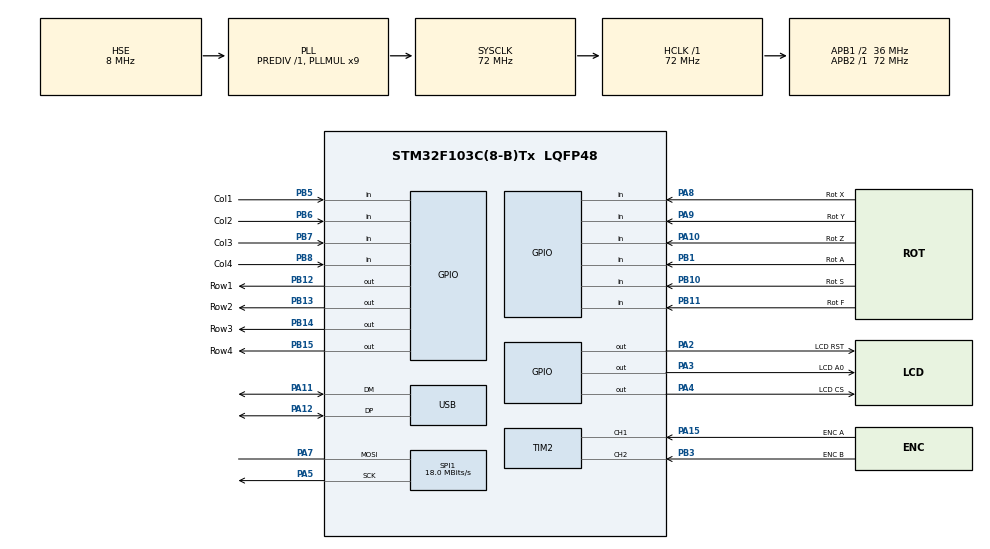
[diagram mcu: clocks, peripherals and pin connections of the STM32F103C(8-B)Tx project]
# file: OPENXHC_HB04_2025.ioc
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Dma.Request0=SPI1_TX
Dma.SPI1_TX.0.Direction=DMA_MEMORY_TO_PERIPH
Dma.SPI1_TX.0.Instance=DMA1_Channel3
Dma.SPI1_TX.0.MemDataAlignment=DMA_MDATAALIGN_BYTE
Dma.SPI1_TX.0.MemInc=DMA_MINC_ENABLE
Dma.SPI1_TX.0.Mode=DMA_NORMAL
Dma.SPI1_TX.0.PeriphDataAlignment=DMA_PDATAALIGN_BYTE
Dma.SPI1_TX.0.PeriphInc=DMA_PINC_DISABLE
Dma.SPI1_TX.0.Priority=DMA_PRIORITY_HIGH
Mcu.Family=STM32F1
Mcu.Name=STM32F103C(8-B)Tx
Mcu.Package=LQFP48
NVIC.DMA1_Channel3_IRQn=true\:0\:0\:false\:false\:true\:false\:true\:true
NVIC.PriorityGroup=NVIC_PRIORITYGROUP_4
NVIC.USB_LP_CAN1_RX0_IRQn=true\:0\:0\:false\:false\:true\:false\:true\:true
PA10.GPIO_Label=Rot Z
PA10.GPIO_PuPd=GPIO_PULLUP
PA10.Signal=GPIO_Input
PA11.Mode=Device
PA11.Signal=USB_DM
PA12.Mode=Device
PA12.Signal=USB_DP
PA13.Mode=Serial_Wire
PA13.Signal=SYS_JTMS-SWDIO
PA14.Mode=Serial_Wire
PA14.Signal=SYS_JTCK-SWCLK
PA15.GPIO_Label=ENC A
PA15.GPIO_PuPd=GPIO_PULLUP
PA15.Signal=S_TIM2_CH1_ETR
PA2.GPIO_Label=LCD RST
PA2.Signal=GPIO_Output
PA3.GPIO_Label=LCD A0
PA3.Signal=GPIO_Output
PA4.GPIO_Label=LCD CS
PA4.Signal=GPIO_Output
PA5.Mode=Simplex_Bidirectional_Master
PA5.Signal=SPI1_SCK
PA7.Mode=Simplex_Bidirectional_Master
PA7.Signal=SPI1_MOSI
PA8.GPIO_Label=Rot X
PA8.GPIO_PuPd=GPIO_PULLUP
PA8.Signal=GPIO_Input
PA9.GPIO_Label=Rot Y
PA9.GPIO_PuPd=GPIO_PULLUP
PA9.Signal=GPIO_Input
PB1.GPIO_Label=Rot A
PB1.GPIO_PuPd=GPIO_PULLUP
PB1.Signal=GPIO_Input
PB10.GPIO_Label=Rot S
PB10.GPIO_PuPd=GPIO_PULLUP
PB10.Signal=GPIO_Input
PB11.GPIO_Label=Rot F
PB11.GPIO_PuPd=GPIO_PULLUP
PB11.Signal=GPIO_Input
PB12.GPIO_Label=Row1
PB12.GPIO_ModeDefaultOutputPP=GPIO_MODE_OUTPUT_OD
PB12.GPIO_PuPd=GPIO_NOPULL
PB12.Signal=GPIO_Output
PB13.GPIO_Label=Row2
PB13.GPIO_ModeDefaultOutputPP=GPIO_MODE_OUTPUT_OD
PB13.GPIO_PuPd=GPIO_NOPULL
PB13.Signal=GPIO_Output
PB14.GPIO_Label=Row3
PB14.GPIO_ModeDefaultOutputPP=GPIO_MODE_OUTPUT_OD
PB14.GPIO_PuPd=GPIO_NOPULL
PB14.Signal=GPIO_Output
PB15.GPIO_Label=Row4
PB15.GPIO_ModeDefaultOutputPP=GPIO_MODE_OUTPUT_OD
PB15.GPIO_PuPd=GPIO_NOPULL
PB15.Signal=GPIO_Output
PB3.GPIO_Label=ENC B
PB3.GPIO_PuPd=GPIO_PULLUP
PB3.Signal=S_TIM2_CH2
PB5.GPIO_Label=Col1
PB5.GPIO_PuPd=GPIO_PULLUP
PB5.Signal=GPIO_Input
PB6.GPIO_Label=Col2
PB6.GPIO_PuPd=GPIO_PULLUP
PB6.Signal=GPIO_Input
PB7.GPIO_Label=Col3
PB7.GPIO_PuPd=GPIO_PULLUP
PB7.Signal=GPIO_Input
PB8.GPIO_Label=Col4
PB8.GPIO_PuPd=GPIO_PULLUP
PB8.Signal=GPIO_Input
PD0-OSC_IN.Mode=HSE-External-Oscillator
PD0-OSC_IN.Signal=RCC_OSC_IN
PD1-OSC_OUT.Mode=HSE-External-Oscillator
PD1-OSC_OUT.Signal=RCC_OSC_OUT
ProjectManager.HeapSize=0x200
ProjectManager.StackSize=0x400
ProjectManager.TargetToolchain=STM32CubeIDE
RCC.AHBFreq_Value=72000000
RCC.APB1CLKDivider=RCC_HCLK_DIV2
RCC.APB1Freq_Value=36000000
RCC.APB1TimFreq_Value=72000000
RCC.APB2Freq_Value=72000000
RCC.APB2TimFreq_Value=72000000
RCC.HCLKFreq_Value=72000000
RCC.PLLMUL=RCC_PLL_MUL9
RCC.SYSCLKFreq_VALUE=72000000
RCC.SYSCLKSource=RCC_SYSCLKSOURCE_PLLCLK
RCC.USBFreq_Value=48000000
RCC.USBPrescaler=RCC_USBCLKSOURCE_PLL_DIV1_5
SH.S_TIM2_CH1_ETR.0=TIM2_CH1,Encoder_Interface
SH.S_TIM2_CH2.0=TIM2_CH2,Encoder_Interface
SPI1.BaudRatePrescaler=SPI_BAUDRATEPRESCALER_4
SPI1.CalculateBaudRate=18.0 MBits/s
SPI1.Direction=SPI_DIRECTION_1LINE
SPI1.Mode=SPI_MODE_MASTER
SPI1.VirtualType=VM_MASTER
TIM2.IC1Filter=4
TIM2.IC2Filter=4
USB_DEVICE.CLASS_NAME_FS=CUSTOM_HID
USB_DEVICE.USBD_CUSTOM_HID_REPORT_DESC_SIZE=41
USB_DEVICE.VirtualMode=CustomHid
USB_DEVICE.VirtualModeFS=Custom_Hid_FS
VP_USB_DEVICE_VS_USB_DEVICE_CUSTOM_HID_FS.Mode=CUSTOM_HID_FS
board=custom

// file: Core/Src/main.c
/* USER CODE BEGIN Header */
/**
  ******************************************************************************
  * @file           : main.c
  * @brief          : Main program body
  ******************************************************************************
  * @attention
  *
  * Copyright (c) 2025 STMicroelectronics.
  * All rights reserved.
  *
  * This software is licensed under terms that can be found in the LICENSE file
  * in the root directory of this software component.
  * If no LICENSE file comes with this software, it is provided AS-IS.
  *
  ******************************************************************************
  */
/* USER CODE END Header */
#include "main.h"
#include "dma.h"
#include "spi.h"
#include "tim.h"
#include "usb_device.h"
#include "gpio.h"

/* USER CODE BEGIN Includes */
#include "st7735.h"
#include "fonts.h"
#include "ui.h"
#include "xhc_integration.h"
/* USER CODE END Includes */

void SystemClock_Config(void);

int main(void)
{

  /* MCU Configuration--------------------------------------------------------*/

  /* Reset of all peripherals, Initializes the Flash interface and the Systick. */
  HAL_Init();

  /* Configure the system clock */
  SystemClock_Config();

  /* Initialize all configured peripherals */
  MX_GPIO_Init();
  MX_DMA_Init();
  MX_SPI1_Init();
  MX_USB_DEVICE_Init();
  MX_TIM2_Init();
  /* USER CODE BEGIN 2 */
  ST7735_Init();
  xhc_init();
  UI_DrawStatic();

  // Farbflächen zum schnellen Check
  //ST7735_FillScreen(ST7735_WHITE);

  /* USER CODE END 2 */

  /* Infinite loop */
  /* USER CODE BEGIN WHILE */
  while (1)
  {
	  xhc_main_loop();

	    // neue Position berechnen

    /* USER CODE END WHILE */

  }
}

void SystemClock_Config(void)
{
  RCC_OscInitTypeDef RCC_OscInitStruct = {0};
  RCC_ClkInitTypeDef RCC_ClkInitStruct = {0};
  RCC_PeriphCLKInitTypeDef PeriphClkInit = {0};

  /** Initializes the RCC Oscillators according to the specified parameters
  * in the RCC_OscInitTypeDef structure.
  */
  RCC_OscInitStruct.OscillatorType = RCC_OSCILLATORTYPE_HSE;
  RCC_OscInitStruct.HSEState = RCC_HSE_ON;
  RCC_OscInitStruct.HSEPredivValue = RCC_HSE_PREDIV_DIV1;
  RCC_OscInitStruct.HSIState = RCC_HSI_ON;
  RCC_OscInitStruct.PLL.PLLState = RCC_PLL_ON;
  RCC_OscInitStruct.PLL.PLLSource = RCC_PLLSOURCE_HSE;
  RCC_OscInitStruct.PLL.PLLMUL = RCC_PLL_MUL9;
  if (HAL_RCC_OscConfig(&RCC_OscInitStruct) != HAL_OK)
  {
    Error_Handler();
  }

  /** Initializes the CPU, AHB and APB buses clocks
  */
  RCC_ClkInitStruct.ClockType = RCC_CLOCKTYPE_HCLK|RCC_CLOCKTYPE_SYSCLK
                              |RCC_CLOCKTYPE_PCLK1|RCC_CLOCKTYPE_PCLK2;
  RCC_ClkInitStruct.SYSCLKSource = RCC_SYSCLKSOURCE_PLLCLK;
  RCC_ClkInitStruct.AHBCLKDivider = RCC_SYSCLK_DIV1;
  RCC_ClkInitStruct.APB1CLKDivider = RCC_HCLK_DIV2;
  RCC_ClkInitStruct.APB2CLKDivider = RCC_HCLK_DIV1;

  if (HAL_RCC_ClockConfig(&RCC_ClkInitStruct, FLASH_LATENCY_2) != HAL_OK)
  {
    Error_Handler();
  }
  PeriphClkInit.PeriphClockSelection = RCC_PERIPHCLK_USB;
  PeriphClkInit.UsbClockSelection = RCC_USBCLKSOURCE_PLL_DIV1_5;
  if (HAL_RCCEx_PeriphCLKConfig(&PeriphClkInit) != HAL_OK)
  {
    Error_Handler();
  }
}

void Error_Handler(void)
{
  __disable_irq();
  while (1)
  {
  }
}
